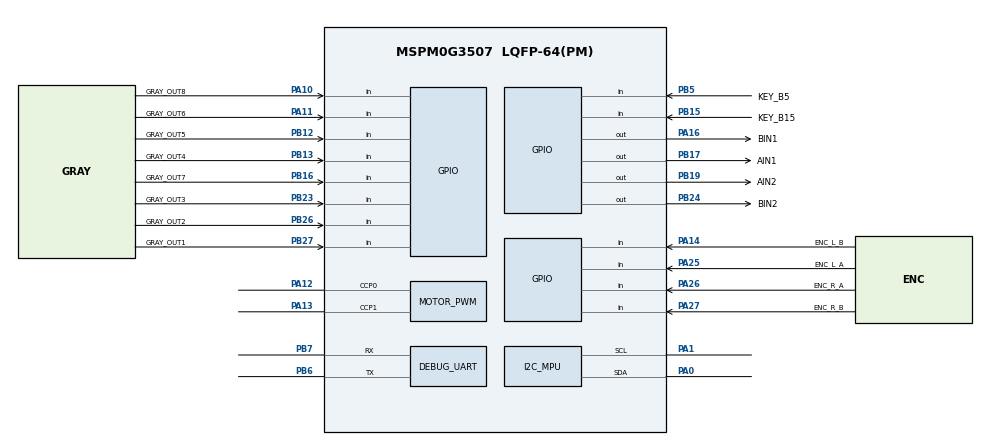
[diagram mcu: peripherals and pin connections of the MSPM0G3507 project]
/**
 * PID speed-loop test for the two-wheel car.
 *
 * Pin source: E:\EmbeddedDevelopment\二驱小车new.xlsx
 * Mapping required by the user: rear-drive car, TB6612 A channel = right rear,
 * TB6612 B channel = left rear.
 */
//@cliArgs --device "MSPM0G350X" --package "LQFP-64(PM)" --part "Default"
//@v2CliArgs --device "MSPM0G3507" --package "LQFP-64(PM)"
// @cliArgs --board /ti/boards/LP_MSPM0G3507 --rtos nortos

const Board  = scripting.addModule("/ti/driverlib/Board", {}, false);
const GPIO   = scripting.addModule("/ti/driverlib/GPIO", {}, false);
const I2C    = scripting.addModule("/ti/driverlib/I2C", {}, false);
const PWM    = scripting.addModule("/ti/driverlib/PWM", {}, false);
const SYSCTL = scripting.addModule("/ti/driverlib/SYSCTL");
const UART   = scripting.addModule("/ti/driverlib/UART", {}, false);

const GPIO_DIR     = GPIO.addInstance();
const GPIO_INPUTS  = GPIO.addInstance();
const I2C_MPU      = I2C.addInstance();
const MOTOR_PWM    = PWM.addInstance();
const DEBUG_UART   = UART.addInstance();

Board.peripheral.$assign = "DEBUGSS";

SYSCTL.forceDefaultClkConfig = true;
SYSCTL.clockTreeEn = true;

GPIO_DIR.$name = "GPIO_MOTOR_DIR";
GPIO_DIR.associatedPins.create(4);
GPIO_DIR.associatedPins[0].$name = "AIN1";
GPIO_DIR.associatedPins[0].initialValue = "CLEARED";
GPIO_DIR.associatedPins[0].pin.$assign = "PB17";
GPIO_DIR.associatedPins[1].$name = "AIN2";
GPIO_DIR.associatedPins[1].initialValue = "CLEARED";
GPIO_DIR.associatedPins[1].pin.$assign = "PB19";
GPIO_DIR.associatedPins[2].$name = "BIN1";
GPIO_DIR.associatedPins[2].initialValue = "CLEARED";
GPIO_DIR.associatedPins[2].pin.$assign = "PA16";
GPIO_DIR.associatedPins[3].$name = "BIN2";
GPIO_DIR.associatedPins[3].initialValue = "CLEARED";
GPIO_DIR.associatedPins[3].pin.$assign = "PB24";

GPIO_INPUTS.$name = "GPIO_CAR_INPUTS";
GPIO_INPUTS.associatedPins.create(14);
GPIO_INPUTS.associatedPins[0].$name = "KEY_B5";
GPIO_INPUTS.associatedPins[0].direction = "INPUT";
GPIO_INPUTS.associatedPins[0].internalResistor = "PULL_UP";
GPIO_INPUTS.associatedPins[0].pin.$assign = "PB5";
GPIO_INPUTS.associatedPins[1].$name = "KEY_B15";
GPIO_INPUTS.associatedPins[1].direction = "INPUT";
GPIO_INPUTS.associatedPins[1].internalResistor = "PULL_UP";
GPIO_INPUTS.associatedPins[1].pin.$assign = "PB15";
GPIO_INPUTS.associatedPins[2].$name = "GRAY_OUT1";
GPIO_INPUTS.associatedPins[2].direction = "INPUT";
GPIO_INPUTS.associatedPins[2].internalResistor = "PULL_UP";
GPIO_INPUTS.associatedPins[2].pin.$assign = "PB27";
GPIO_INPUTS.associatedPins[3].$name = "GRAY_OUT2";
GPIO_INPUTS.associatedPins[3].direction = "INPUT";
GPIO_INPUTS.associatedPins[3].internalResistor = "PULL_UP";
GPIO_INPUTS.associatedPins[3].pin.$assign = "PB26";
GPIO_INPUTS.associatedPins[4].$name = "GRAY_OUT3";
GPIO_INPUTS.associatedPins[4].direction = "INPUT";
GPIO_INPUTS.associatedPins[4].internalResistor = "PULL_UP";
GPIO_INPUTS.associatedPins[4].pin.$assign = "PB23";
GPIO_INPUTS.associatedPins[5].$name = "GRAY_OUT4";
GPIO_INPUTS.associatedPins[5].direction = "INPUT";
GPIO_INPUTS.associatedPins[5].internalResistor = "PULL_UP";
GPIO_INPUTS.associatedPins[5].pin.$assign = "PB13";
GPIO_INPUTS.associatedPins[6].$name = "GRAY_OUT5";
GPIO_INPUTS.associatedPins[6].direction = "INPUT";
GPIO_INPUTS.associatedPins[6].internalResistor = "PULL_UP";
GPIO_INPUTS.associatedPins[6].pin.$assign = "PB12";
GPIO_INPUTS.associatedPins[7].$name = "GRAY_OUT6";
GPIO_INPUTS.associatedPins[7].direction = "INPUT";
GPIO_INPUTS.associatedPins[7].internalResistor = "PULL_UP";
GPIO_INPUTS.associatedPins[7].pin.$assign = "PA11";
GPIO_INPUTS.associatedPins[8].$name = "GRAY_OUT7";
GPIO_INPUTS.associatedPins[8].direction = "INPUT";
GPIO_INPUTS.associatedPins[8].internalResistor = "PULL_UP";
GPIO_INPUTS.associatedPins[8].pin.$assign = "PB16";
GPIO_INPUTS.associatedPins[9].$name = "GRAY_OUT8";
GPIO_INPUTS.associatedPins[9].direction = "INPUT";
GPIO_INPUTS.associatedPins[9].internalResistor = "PULL_UP";
GPIO_INPUTS.associatedPins[9].pin.$assign = "PA10";
GPIO_INPUTS.associatedPins[10].$name = "ENC_R_A";
GPIO_INPUTS.associatedPins[10].direction = "INPUT";
GPIO_INPUTS.associatedPins[10].internalResistor = "PULL_UP";
GPIO_INPUTS.associatedPins[10].interruptEn = true;
GPIO_INPUTS.associatedPins[10].polarity = "RISE_FALL";
GPIO_INPUTS.associatedPins[10].pin.$assign = "PA26";
GPIO_INPUTS.associatedPins[11].$name = "ENC_R_B";
GPIO_INPUTS.associatedPins[11].direction = "INPUT";
GPIO_INPUTS.associatedPins[11].internalResistor = "PULL_UP";
GPIO_INPUTS.associatedPins[11].interruptEn = true;
GPIO_INPUTS.associatedPins[11].polarity = "RISE_FALL";
GPIO_INPUTS.associatedPins[11].pin.$assign = "PA27";
GPIO_INPUTS.associatedPins[12].$name = "ENC_L_A";
GPIO_INPUTS.associatedPins[12].direction = "INPUT";
GPIO_INPUTS.associatedPins[12].internalResistor = "PULL_UP";
GPIO_INPUTS.associatedPins[12].interruptEn = true;
GPIO_INPUTS.associatedPins[12].polarity = "RISE_FALL";
GPIO_INPUTS.associatedPins[12].pin.$assign = "PA25";
GPIO_INPUTS.associatedPins[13].$name = "ENC_L_B";
GPIO_INPUTS.associatedPins[13].direction = "INPUT";
GPIO_INPUTS.associatedPins[13].internalResistor = "PULL_UP";
GPIO_INPUTS.associatedPins[13].interruptEn = true;
GPIO_INPUTS.associatedPins[13].polarity = "RISE_FALL";
GPIO_INPUTS.associatedPins[13].pin.$assign = "PA14";

MOTOR_PWM.$name = "MOTOR_PWM";
MOTOR_PWM.timerCount = 1600;
MOTOR_PWM.dutyArgs = "[0,0,0,0]";
MOTOR_PWM.enableShadowLoad = false;
MOTOR_PWM.timerStartTimer = true;
MOTOR_PWM.peripheral.$assign = "TIMG0";
MOTOR_PWM.peripheral.ccp0Pin.$assign = "PA12";
MOTOR_PWM.peripheral.ccp1Pin.$assign = "PA13";
MOTOR_PWM.PWM_CHANNEL_0.$name = "PWMA_RIGHT_REAR";
MOTOR_PWM.PWM_CHANNEL_1.$name = "PWMB_LEFT_REAR";

DEBUG_UART.$name = "UART_0";
DEBUG_UART.profile = "CONFIG_PROFILE_1";
DEBUG_UART.peripheral.$assign = "UART1";
DEBUG_UART.targetBaudRate = 9600;
DEBUG_UART.enableInternalLoopback = false;
DEBUG_UART.enableFIFO = false;
DEBUG_UART.enabledInterrupts = ["RX"];
DEBUG_UART.peripheral.txPin.$assign = "PB6";
DEBUG_UART.peripheral.rxPin.$assign = "PB7";

I2C_MPU.$name = "I2C_MPU6050";
I2C_MPU.basicEnableController = true;
I2C_MPU.basicControllerBusSpeed = 400000;
I2C_MPU.advAnalogGlitchFilter = "DISABLED";
I2C_MPU.advControllerTXFIFOTRIG = "BYTES_1";
I2C_MPU.peripheral.$assign = "I2C0";
I2C_MPU.peripheral.sdaPin.$assign = "PA0";
I2C_MPU.peripheral.sclPin.$assign = "PA1";
I2C_MPU.sdaPinConfig.enableConfig = true;
I2C_MPU.sclPinConfig.enableConfig = true;
